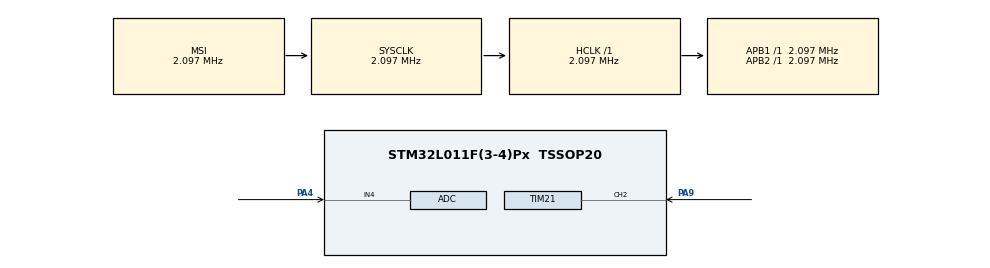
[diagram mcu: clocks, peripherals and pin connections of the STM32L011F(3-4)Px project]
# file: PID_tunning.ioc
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Mcu.Family=STM32L0
Mcu.Name=STM32L011F(3-4)Px
Mcu.Package=TSSOP20
NVIC.ADC1_COMP_IRQn=true\:0\:0\:false\:false\:true\:true\:true\:true
NVIC.TIM21_IRQn=true\:0\:0\:false\:false\:true\:true\:true\:true
PA13.Mode=Serial_Wire
PA13.Signal=SYS_SWDIO
PA14.Mode=Serial_Wire
PA14.Signal=SYS_SWCLK
PA4.Mode=IN4
PA4.Signal=ADC_IN4
PA9.Signal=S_TIM21_CH2
ProjectManager.HeapSize=0x200
ProjectManager.StackSize=0x400
ProjectManager.TargetToolchain=STM32CubeIDE
RCC.AHBFreq_Value=2097000
RCC.APB1Freq_Value=2097000
RCC.APB1TimFreq_Value=2097000
RCC.APB2Freq_Value=2097000
RCC.APB2TimFreq_Value=2097000
RCC.HSE_VALUE=8000000
RCC.HSI16_VALUE=16000000
RCC.HSI_VALUE=16000000
RCC.LSE_VALUE=32768
RCC.MSI_VALUE=2097000
RCC.SYSCLKFreq_VALUE=2097000
RCC.VCOOutputFreq_Value=48000000
SH.S_TIM21_CH2.0=TIM21_CH2,PWM_Input_2
TIM21.ICPolarity_1=TIM_INPUTCHANNELPOLARITY_FALLING
TIM21.Period=10000
TIM21.Prescaler=16-1
VP_TIM21_VS_ClockSourceINT.Mode=Internal
board=custom

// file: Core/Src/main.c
/* USER CODE BEGIN Header */
/**
  ******************************************************************************
  * @file           : main.c
  * @brief          : Main program body
  ******************************************************************************
  * @attention
  *
  * Copyright (c) 2023 STMicroelectronics.
  * All rights reserved.
  *
  * This software is licensed under terms that can be found in the LICENSE file
  * in the root directory of this software component.
  * If no LICENSE file comes with this software, it is provided AS-IS.
  *
  ******************************************************************************
  */
/* USER CODE END Header */
#include "main.h"

ADC_HandleTypeDef hadc;

TIM_HandleTypeDef htim21;

void SystemClock_Config(void);
static void MX_GPIO_Init(void);
static void MX_ADC_Init(void);
static void MX_TIM21_Init(void);

/* USER CODE BEGIN 0 */
	uint16_t V_meas = 0;
//############################## PWM INPUT##############################
	float Duty_input = 0; //Duty cycle coefficient: 0->0%, 1->100%
	uint32_t PWM_input_period = 0; //Period of the PWM function (counts timer clicks)
	uint32_t PWM_input_pulseON = 0; //Pulse width, of the positive part, on.
	uint32_t Frequency_input = 0;//Frequency of the PWM hole function (Hz)
/* USER CODE END 0 */

int main(void)
{

  /* MCU Configuration--------------------------------------------------------*/

  /* Reset of all peripherals, Initializes the Flash interface and the Systick. */
  HAL_Init();

  /* Configure the system clock */
  SystemClock_Config();

  /* Initialize all configured peripherals */
  MX_GPIO_Init();
  MX_ADC_Init();
  MX_TIM21_Init();
  /* USER CODE BEGIN 2 */
  	  //##############################PWM INPUT##############################
	  // Main channel (Function Period Measure):
	  HAL_TIM_IC_Start_IT(&htim21, TIM_CHANNEL_2);
	  // Indirect channel (Pulse Width Measure):
	  HAL_TIM_IC_Start(&htim21, TIM_CHANNEL_1);
  /* USER CODE END 2 */

  /* Infinite loop */
  while (1)
  {

  }
}

void SystemClock_Config(void)
{
  RCC_OscInitTypeDef RCC_OscInitStruct = {0};
  RCC_ClkInitTypeDef RCC_ClkInitStruct = {0};

  /** Configure the main internal regulator output voltage
  */
  __HAL_PWR_VOLTAGESCALING_CONFIG(PWR_REGULATOR_VOLTAGE_SCALE1);

  /** Initializes the RCC Oscillators according to the specified parameters
  * in the RCC_OscInitTypeDef structure.
  */
  RCC_OscInitStruct.OscillatorType = RCC_OSCILLATORTYPE_MSI;
  RCC_OscInitStruct.MSIState = RCC_MSI_ON;
  RCC_OscInitStruct.MSICalibrationValue = 0;
  RCC_OscInitStruct.MSIClockRange = RCC_MSIRANGE_5;
  RCC_OscInitStruct.PLL.PLLState = RCC_PLL_NONE;
  if (HAL_RCC_OscConfig(&RCC_OscInitStruct) != HAL_OK)
  {
    Error_Handler();
  }

  /** Initializes the CPU, AHB and APB buses clocks
  */
  RCC_ClkInitStruct.ClockType = RCC_CLOCKTYPE_HCLK|RCC_CLOCKTYPE_SYSCLK
                              |RCC_CLOCKTYPE_PCLK1|RCC_CLOCKTYPE_PCLK2;
  RCC_ClkInitStruct.SYSCLKSource = RCC_SYSCLKSOURCE_MSI;
  RCC_ClkInitStruct.AHBCLKDivider = RCC_SYSCLK_DIV1;
  RCC_ClkInitStruct.APB1CLKDivider = RCC_HCLK_DIV1;
  RCC_ClkInitStruct.APB2CLKDivider = RCC_HCLK_DIV1;

  if (HAL_RCC_ClockConfig(&RCC_ClkInitStruct, FLASH_LATENCY_0) != HAL_OK)
  {
    Error_Handler();
  }
}

static void MX_ADC_Init(void)
{

  ADC_ChannelConfTypeDef sConfig = {0};

  /** Configure the global features of the ADC (Clock, Resolution, Data Alignment and number of conversion)
  */
  hadc.Instance = ADC1;
  hadc.Init.OversamplingMode = DISABLE;
  hadc.Init.ClockPrescaler = ADC_CLOCK_SYNC_PCLK_DIV1;
  hadc.Init.Resolution = ADC_RESOLUTION_12B;
  hadc.Init.SamplingTime = ADC_SAMPLETIME_1CYCLE_5;
  hadc.Init.ScanConvMode = ADC_SCAN_DIRECTION_FORWARD;
  hadc.Init.DataAlign = ADC_DATAALIGN_RIGHT;
  hadc.Init.ContinuousConvMode = DISABLE;
  hadc.Init.DiscontinuousConvMode = DISABLE;
  hadc.Init.ExternalTrigConvEdge = ADC_EXTERNALTRIGCONVEDGE_NONE;
  hadc.Init.ExternalTrigConv = ADC_SOFTWARE_START;
  hadc.Init.DMAContinuousRequests = DISABLE;
  hadc.Init.EOCSelection = ADC_EOC_SINGLE_CONV;
  hadc.Init.Overrun = ADC_OVR_DATA_PRESERVED;
  hadc.Init.LowPowerAutoWait = DISABLE;
  hadc.Init.LowPowerFrequencyMode = ENABLE;
  hadc.Init.LowPowerAutoPowerOff = DISABLE;
  if (HAL_ADC_Init(&hadc) != HAL_OK)
  {
    Error_Handler();
  }

  /** Configure for the selected ADC regular channel to be converted.
  */
  sConfig.Channel = ADC_CHANNEL_4;
  sConfig.Rank = ADC_RANK_CHANNEL_NUMBER;
  if (HAL_ADC_ConfigChannel(&hadc, &sConfig) != HAL_OK)
  {
    Error_Handler();
  }

}

static void MX_TIM21_Init(void)
{

  TIM_ClockConfigTypeDef sClockSourceConfig = {0};
  TIM_SlaveConfigTypeDef sSlaveConfig = {0};
  TIM_IC_InitTypeDef sConfigIC = {0};
  TIM_MasterConfigTypeDef sMasterConfig = {0};

  htim21.Instance = TIM21;
  htim21.Init.Prescaler = 16-1;
  htim21.Init.CounterMode = TIM_COUNTERMODE_UP;
  htim21.Init.Period = 10000;
  htim21.Init.ClockDivision = TIM_CLOCKDIVISION_DIV1;
  htim21.Init.AutoReloadPreload = TIM_AUTORELOAD_PRELOAD_DISABLE;
  if (HAL_TIM_Base_Init(&htim21) != HAL_OK)
  {
    Error_Handler();
  }
  sClockSourceConfig.ClockSource = TIM_CLOCKSOURCE_INTERNAL;
  if (HAL_TIM_ConfigClockSource(&htim21, &sClockSourceConfig) != HAL_OK)
  {
    Error_Handler();
  }
  if (HAL_TIM_IC_Init(&htim21) != HAL_OK)
  {
    Error_Handler();
  }
  sSlaveConfig.SlaveMode = TIM_SLAVEMODE_RESET;
  sSlaveConfig.InputTrigger = TIM_TS_TI2FP2;
  sSlaveConfig.TriggerPolarity = TIM_INPUTCHANNELPOLARITY_RISING;
  sSlaveConfig.TriggerPrescaler = TIM_ICPSC_DIV1;
  sSlaveConfig.TriggerFilter = 0;
  if (HAL_TIM_SlaveConfigSynchro(&htim21, &sSlaveConfig) != HAL_OK)
  {
    Error_Handler();
  }
  sConfigIC.ICPolarity = TIM_INPUTCHANNELPOLARITY_FALLING;
  sConfigIC.ICSelection = TIM_ICSELECTION_INDIRECTTI;
  sConfigIC.ICPrescaler = TIM_ICPSC_DIV1;
  sConfigIC.ICFilter = 0;
  if (HAL_TIM_IC_ConfigChannel(&htim21, &sConfigIC, TIM_CHANNEL_1) != HAL_OK)
  {
    Error_Handler();
  }
  sConfigIC.ICPolarity = TIM_INPUTCHANNELPOLARITY_RISING;
  sConfigIC.ICSelection = TIM_ICSELECTION_DIRECTTI;
  if (HAL_TIM_IC_ConfigChannel(&htim21, &sConfigIC, TIM_CHANNEL_2) != HAL_OK)
  {
    Error_Handler();
  }
  sMasterConfig.MasterOutputTrigger = TIM_TRGO_RESET;
  sMasterConfig.MasterSlaveMode = TIM_MASTERSLAVEMODE_DISABLE;
  if (HAL_TIMEx_MasterConfigSynchronization(&htim21, &sMasterConfig) != HAL_OK)
  {
    Error_Handler();
  }

}

static void MX_GPIO_Init(void)
{

  /* GPIO Ports Clock Enable */
  __HAL_RCC_GPIOA_CLK_ENABLE();

}

/* USER CODE BEGIN 4 */
void HAL_ADC_ConvCpltCallback(ADC_HandleTypeDef* hadc1)
{
	V_meas = HAL_ADC_GetValue(hadc1);
}

void HAL_TIM_IC_CaptureCallback(TIM_HandleTypeDef *htim){

	// Check which version of the timer triggered
	if(htim == &htim21)
	{ //It's called each 10*10000/32000000=3.215ms, as the input PWM frequency is 400Hz
		// If the interrupt is triggered by channel 2
		if (htim->Channel == HAL_TIM_ACTIVE_CHANNEL_2){
			// Read the IC value
			PWM_input_period = HAL_TIM_ReadCapturedValue(htim, TIM_CHANNEL_2);
			//If it ́s not the initial 0 capture (=>no pulse registered)
			if (PWM_input_period != 0){
				PWM_input_pulseON = HAL_TIM_ReadCapturedValue(htim, TIM_CHANNEL_1);
				// Compute the Duty Cycle
				Duty_input = (float)(PWM_input_pulseON)/(float)PWM_input_period;
				//Compute the frequency of the PWM. 32000000 is the timer frequency
				//Frequency_input = 32000000/(PWM_input_period);//Divide also by prescaler if us

				//Computing the Thrust desired.
				//Thrust_desired = linear_map(Duty_input, 0.5, 1, 0, 25);//Depends on the comunication protocol?
			}
		}
		HAL_ADC_Start_IT(&hadc);
		//Duty_output = Duty_input;

	}
}
/* USER CODE END 4 */

void Error_Handler(void)
{
  __disable_irq();
  while (1)
  {
  }
}
